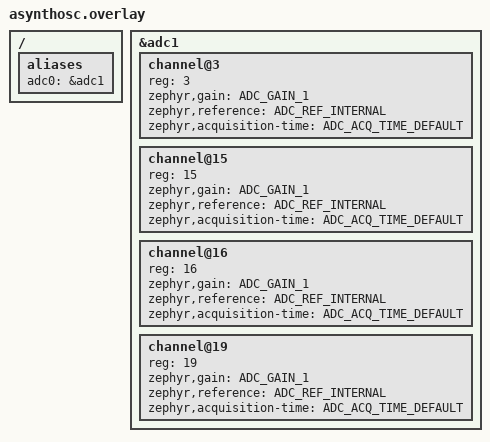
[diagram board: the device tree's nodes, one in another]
/*
 * Copyright (c) 2024 Centro de Inovacao EDGE
 *
 * SPDX-License-Identifier: Apache-2.0
 */

/ {
	aliases {
		adc0 = &adc1;
	};
};

&adc1 {
	#address-cells = <1>;
	#size-cells = <0>;

	channel@3 {
		reg = <3>;
		zephyr,gain = "ADC_GAIN_1";
		zephyr,reference = "ADC_REF_INTERNAL";
		zephyr,acquisition-time = <ADC_ACQ_TIME_DEFAULT>;
	};

	channel@15 {
		reg = <15>;
		zephyr,gain = "ADC_GAIN_1";
		zephyr,reference = "ADC_REF_INTERNAL";
		zephyr,acquisition-time = <ADC_ACQ_TIME_DEFAULT>;
	};

	channel@16 {
		reg = <16>;
		zephyr,gain = "ADC_GAIN_1";
		zephyr,reference = "ADC_REF_INTERNAL";
		zephyr,acquisition-time = <ADC_ACQ_TIME_DEFAULT>;
	};

	channel@19 {
		reg = <19>;
		zephyr,gain = "ADC_GAIN_1";
		zephyr,reference = "ADC_REF_INTERNAL";
		zephyr,acquisition-time = <ADC_ACQ_TIME_DEFAULT>;
	};
};
